VERSION ""

NS_ :

BS_:
BU_: Unnamed9933
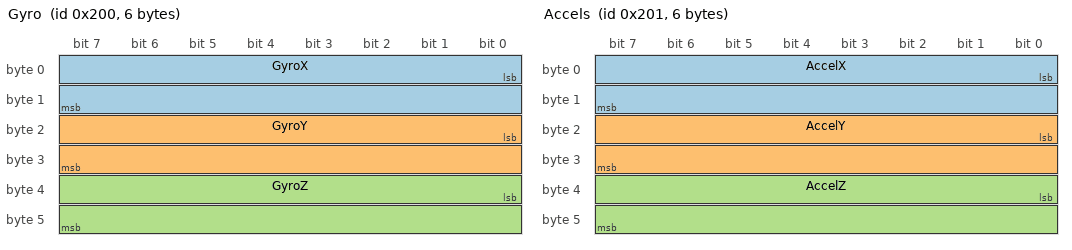
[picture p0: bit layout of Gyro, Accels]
BO_ 512 Gyro: 6 Vector__XXX
   SG_ GyroX : 0|16@1- (0.0305176,0) [0|1] "dps" Vector__XXX
   SG_ GyroY : 16|16@1- (0.0305176,0) [0|1] "dps" Vector__XXX
   SG_ GyroZ : 32|16@1- (0.0305176,0) [0|1] "dps" Vector__XXX

BO_ 513 Accels: 6 Vector__XXX
   SG_ AccelX : 0|16@1- (0.000244141,0) [0|1] "g" Vector__XXX
   SG_ AccelY : 16|16@1- (0.000244141,0) [0|1] "g" Vector__XXX
   SG_ AccelZ : 32|16@1- (0.000244141,0) [0|1] "g" Vector__XXX

BA_DEF_ BO_ "GenMsgBackgroundColor" STRING ;
BA_DEF_ BO_ "GenMsgForegroundColor" STRING ;
BA_DEF_ BO_ "filterlabeling" INT 0 0;
BA_ "GenMsgBackgroundColor" BO_ 512 "#aaffff";
BA_ "GenMsgBackgroundColor" BO_ 513 "#aaffff";
BA_DEF_DEF_ "GenMsgBackgroundColor" "#ffffff";
BA_DEF_DEF_ "GenMsgForegroundColor" "#232629";
BA_DEF_DEF_ "filterlabeling" 1;
